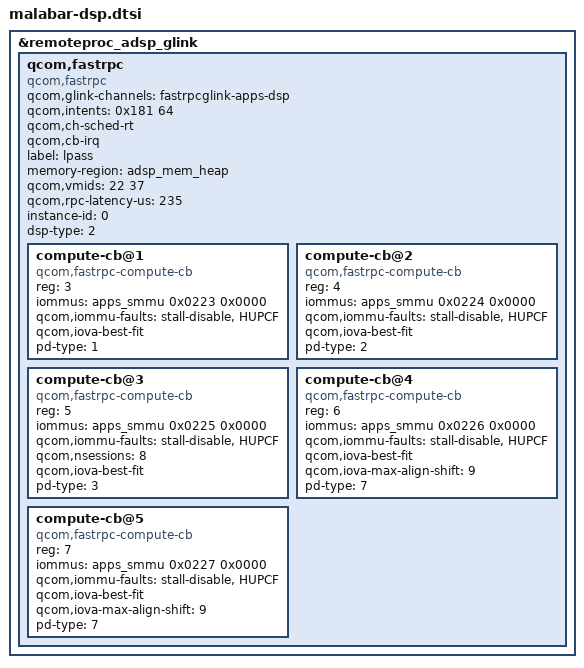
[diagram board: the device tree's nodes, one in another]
// SPDX-License-Identifier: BSD-3-Clause
/*
 * Copyright (c) Qualcomm Technologies, Inc. and/or its subsidiaries.
 */

&remoteproc_adsp_glink {
	qcom,fastrpc {
		compatible = "qcom,fastrpc";
		qcom,glink-channels = "fastrpcglink-apps-dsp";
		qcom,intents = <0x181 64>;
		qcom,ch-sched-rt;
		qcom,cb-irq;
		label = "lpass";
		memory-region = <&adsp_mem_heap>;
		qcom,vmids = <22 37>;
		qcom,rpc-latency-us = <235>;
		instance-id = <0>;
		dsp-type = <2>;

		compute-cb@1 {
			compatible = "qcom,fastrpc-compute-cb";
			reg = <3>;
			iommus = <&apps_smmu 0x0223 0x0000>;
			qcom,iommu-faults = "stall-disable", "HUPCF";
			qcom,iova-best-fit;
			pd-type = <1>;	/* ROOT_PD */
		};

		compute-cb@2 {
			compatible = "qcom,fastrpc-compute-cb";
			reg = <4>;
			iommus = <&apps_smmu 0x0224 0x0000>;
			qcom,iommu-faults = "stall-disable", "HUPCF";
			qcom,iova-best-fit;
			pd-type = <2>;	/* AUDIO_STATICPD */
		};

		compute-cb@3 {
			compatible = "qcom,fastrpc-compute-cb";
			reg = <5>;
			iommus = <&apps_smmu 0x0225 0x0000>;
			qcom,iommu-faults = "stall-disable", "HUPCF";
			qcom,nsessions = <8>;
			qcom,iova-best-fit;
			pd-type = <3>;	/* SENSORS_STATICPD */
		};

		compute-cb@4 {
			compatible = "qcom,fastrpc-compute-cb";
			reg = <6>;
			iommus = <&apps_smmu 0x0226 0x0000>;
			qcom,iommu-faults = "stall-disable", "HUPCF";
			qcom,iova-best-fit;
			qcom,iova-max-align-shift = <9>; /* Set MAX alignment to 2 MB*/
			pd-type = <7>;	/* USERPD */
		};

		compute-cb@5 {
			compatible = "qcom,fastrpc-compute-cb";
			reg = <7>;
			iommus = <&apps_smmu 0x0227 0x0000>;
			qcom,iommu-faults = "stall-disable", "HUPCF";
			qcom,iova-best-fit;
			qcom,iova-max-align-shift = <9>; /* Set MAX alignment to 2 MB*/
			pd-type = <7>;	/* USERPD */
		};
	};
};
